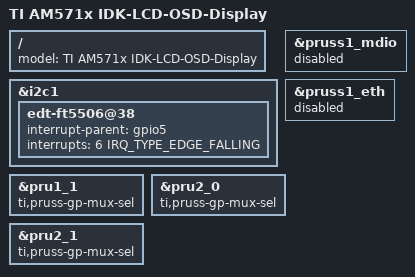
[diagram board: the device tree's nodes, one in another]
#include <dt-bindings/interrupt-controller/irq.h>

/ {
    fragment@201 {
        target-path = "/";
        __overlay__ {
            model = "TI AM571x IDK-LCD-OSD-Display";
            /* path-refs not supported for overlays */
            /* aliases {
                ethernet2 = &pruss2_emac0;
                ethernet3 = &pruss2_emac1;
            }; */
        };
    };
#if 0
    fragment@202 {
        target = <&touchscreen>;
        __overlay__ {
            interrupt-parent = <&gpio5>;
            interrupts = <6 IRQ_TYPE_EDGE_FALLING>;
        };
    };
#else
    fragment@202 {
        target = <&i2c1>;
        __overlay__ {
            edt-ft5506@38 {
                interrupt-parent = <&gpio5>;
                interrupts = <6 IRQ_TYPE_EDGE_FALLING>;
	    };
        };
    };
#endif
    fragment@203 {
        target = <&pruss1_mdio>;
        __overlay__ {
            status = "disabled";
        };
    };
    fragment@204 {
        target = <&pruss1_eth>;
        __overlay__ {
            status = "disabled";
        };
    };
    fragment@205 {
        target = <&pru1_1>;
        __overlay__ {
            ti,pruss-gp-mux-sel;	/* note that the driver must be capable of handling this */
        };
    };
    fragment@206 {
        target = <&pru2_0>;
        __overlay__ {
            ti,pruss-gp-mux-sel;	/* note that the driver must be capable of handling this */
        };
    };
    fragment@207 {
        target = <&pru2_1>;
        __overlay__ {
            ti,pruss-gp-mux-sel;	/* note that the driver must be capable of handling this */
        };
    };
};
